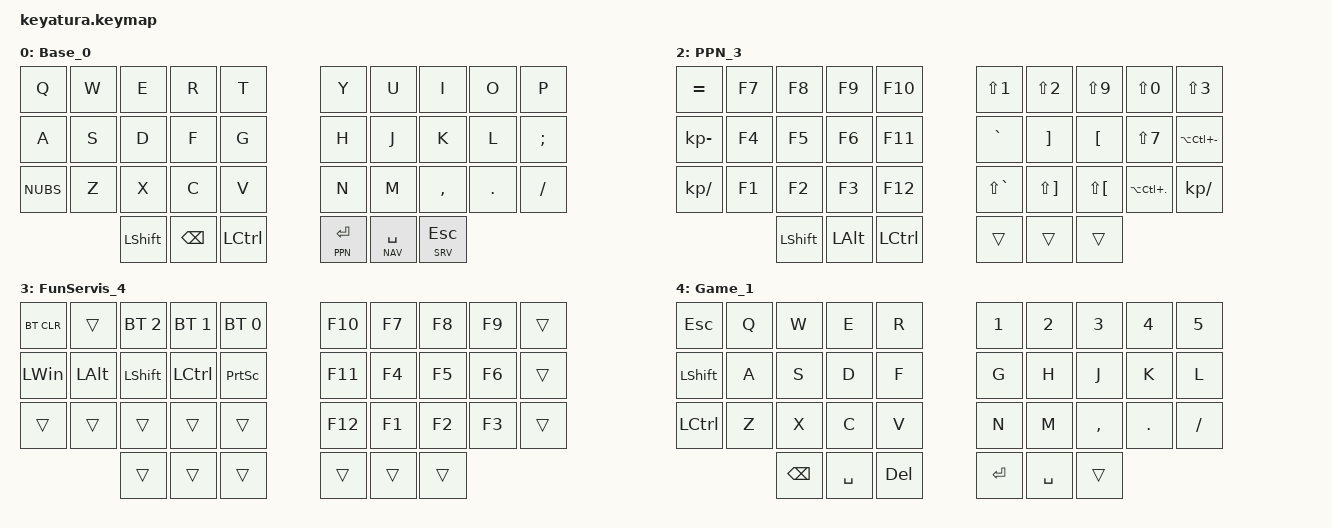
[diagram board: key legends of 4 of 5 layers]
#include <behaviors.dtsi> 
#include <dt-bindings/zmk/bt.h>
#include <dt-bindings/zmk/keys.h>
#include <dt-bindings/zmk/outputs.h>
#include <dt-bindings/zmk/pointing.h>

#include <behaviors/vfx_indicator.dtsi>

#define U_TAPPING_TERM 220
#define U_QUICK_TAP 200

#define BASE  0
#define NAV   1
#define PPN   2
#define SRV   3
#define GAME  4



/ {
    combos {
    compatible = "zmk,combos";
    timeout-ms = <20>;
    require-prior-idle-ms = <250>;

    bootloaderRight {
        bindings = <&bootloader>;
        key-positions = <9 18 27>;
        layers = <0>;
    };
    bootloaderLeft {
        bindings = <&bootloader>;
        key-positions = <0 11 22>;
        layers = <0>;
    };

    combo_normal {
        key-positions = <6 7 8>;
        bindings = <&to BASE>;
    };
    combo_normalleft {
        key-positions = <1 2 3>;
        bindings = <&to BASE>;
        layers = <0 1 2>;
    };
    game {
        bindings = <&tog GAME>;
        key-positions = <18 29>;
    };
    gameleft {
        bindings = <&tog GAME>;
        key-positions = <0 24>;
    };
    combo_SRV {
        key-positions = <27 28>;
        bindings = <&sl SRV>;
        layers = <0 1 2>;
    };
    GoNav {
        bindings = <&tog NAV>;
        key-positions = <5 16>;
    };
    GoPPN {
        bindings = <&tog PPN>;
        key-positions = <0 1 2>;
    };

    Delete {
        bindings = <&kp DELETE>;
        key-positions = <8 9>;
        layers = <0 1 2>;
    };
    Delete2 {
        bindings = <&kp DELETE>;
        key-positions = <7 8>;
        layers = <0 1 2>;
    };

    screenshot {
        bindings = <&kp LG(LS(S))>;
        key-positions = <3 4>;
        layers = <0 1 2>;
    };

    eng {
        bindings = <&kp F16>;
        key-positions = <13 14>;
        layers = <0 1 2>;
    };
    rus {
        bindings = <&kp F17>;
        key-positions = <15 16>;
        layers = <0 1 2>;
    };

    ParaLeft {
        bindings = <&kp LS(N9)>;
        key-positions = <23 24>;
        layers = <0 1 2>;
    };
    greatt {
        bindings = <&kp LC(LA(P))>;
        key-positions = <25 26>;
        layers = <0 1 2>;
    };
    circumflex {
        bindings = <&kp LS(N6)>;
        key-positions = <5 6>;
        layers = <0 1 2>;
    };

    fullscrenRight {
        bindings = <&kp F11>;
        key-positions = <6 15>;
        layers = <0 1 2>;
    };
    fullscreenLeft {
        bindings = <&kp F11>;
        key-positions = <3 14>;
        layers = <0 1 2>;
        };
    };

    behaviors {
        u_mt: u_mt {
            compatible = "zmk,behavior-hold-tap";
            #binding-cells = <2>;
            tapping-term-ms = <U_TAPPING_TERM>;
            quick-tap-ms = <U_QUICK_TAP>;
            flavor = "tap-preferred";
            bindings = <&kp>, <&kp>;
        };

        u_lt: u_lt {
            compatible = "zmk,behavior-hold-tap";
            #binding-cells = <2>;
            tapping-term-ms = <U_TAPPING_TERM>;
            quick-tap-ms = <U_QUICK_TAP>;
            flavor = "tap-preferred";
            bindings = <&mo>, <&kp>;
        };
    };

    keymap {
        compatible = "zmk,keymap";

        Base {
            display-name = "Base_0";
            bindings = <
            // ╭─────────────┬─────────────┬─────────────┬─────────────┬─────────────╮Bse╭─────────────┬─────────────┬─────────────┬─────────────┬─────────────╮
                    &kp Q         &kp W         &kp E         &kp R         &kp T             &kp Y         &kp U         &kp I         &kp O         &kp P
            // ├─────────────┼─────────────┼─────────────┼─────────────┼─────────────┤ 0 ├─────────────┼─────────────┼─────────────┼─────────────┼─────────────┤
                    &kp A         &kp S         &kp D         &kp F         &kp G             &kp H         &kp J         &kp K         &kp L        &kp SEMI
            // ├─────────────┼─────────────┼─────────────┼─────────────┼─────────────┤Bse├─────────────┼─────────────┼─────────────┼─────────────┼─────────────┤
                   &kp NUBS       &kp Z         &kp X         &kp C         &kp V             &kp N         &kp M       &kp COMMA      &kp DOT       &kp FSLH
            // ╰─────────────┴─────────────┼─────────────┼─────────────┼─────────────┤ 0 ├─────────────┼─────────────┼─────────────┼─────────────┴─────────────╯
                                              &kp LSHFT      &kp BSPC     &kp LCTRL        &lt PPN RET  &lt NAV SPACE  &lt SRV ESC  
            //                             ╰─────────────┴─────────────┴─────────────╯Bse╰─────────────┴─────────────┴─────────────╯
            >;
        };

        Navigation {
            display-name = "NavNam_2";
            bindings = <
            // ╭─────────────┬─────────────┬─────────────┬─────────────┬─────────────╮Nav╭─────────────┬─────────────┬─────────────┬─────────────┬─────────────╮
                  &kp EQUAL       &kp N7        &kp N8        &kp N9       &kp RBKT          &kp ESC      &kp PG_UP       &kp UP      &kp PG_DN      &kp F11
            // ├─────────────┼─────────────┼─────────────┼─────────────┼─────────────┤ 1 ├─────────────┼─────────────┼─────────────┼─────────────┼─────────────┤
                 &kp KP_MINUS     &kp N4        &kp N5        &kp N6     &kp KP_PLUS         &kp RET      &kp LEFT      &kp DOWN      &kp RIGHT      &kp LSHF
            // ├─────────────┼─────────────┼─────────────┼─────────────┼─────────────┤Nav├─────────────┼─────────────┼─────────────┼─────────────┼─────────────┤
                 &kp KP_SLASH     &kp N1        &kp N2        &kp N3   &kp KP_MULTIPLY       &kp TAB    &kp C_VOL_DN  &kp C_VOL_UP  &kp LA(LC(DOT)) T&kp LCTRL
            // ╰─────────────┴─────────────┼─────────────┼─────────────┼─────────────┤ 1 ├─────────────┼─────────────┼─────────────┼─────────────┴─────────────╯
                                              &kp SPACE     &kp BSPC       &kp N0            &kp RET      &kp SPACE       &trans
            //                             ╰─────────────┴─────────────┴─────────────╯Nav╰─────────────┴─────────────┴─────────────╯
            >;
        };

        PPN {
            display-name = "PPN_3";
            bindings = <
            // ╭─────────────┬─────────────┬─────────────┬─────────────┬─────────────╮PPN╭─────────────┬─────────────┬─────────────┬─────────────┬─────────────╮
                  &kp EQUAL       &kp F7        &kp F8        &kp F9       &kp F10          &kp LS(N1)    &kp LS(N2)    &kp LS(N9)    &kp LS(N0)    &kp LS(N3)
            // ├─────────────┼─────────────┼─────────────┼─────────────┼─────────────┤ 2 ├─────────────┼─────────────┼─────────────┼─────────────┼─────────────┤
                 &kp KP_MINUS     &kp F4        &kp F5        &kp F6       &kp F11          &kp GRAVE      &kp RBKT      &kp LBKT    &kp LS(N7) &kp LA(LC(MINUS))
            // ├─────────────┼─────────────┼─────────────┼─────────────┼─────────────┤PPN├─────────────┼─────────────┼─────────────┼─────────────┼─────────────┤
                 &kp KP_SLASH     &kp F1        &kp F2        &kp F3       &kp F12        &kp LS(GRAVE)  &kp LS(RBKT) &kp LS(LBKT) &kp LA(LC(DOT)) &kp KP_SLASH
            // ╰─────────────┴─────────────┼─────────────┼─────────────┼─────────────┤ 2 ├─────────────┼─────────────┼─────────────┼─────────────┴─────────────╯
                                              &kp LSHFT      &kp LALT     &kp LCTRL           &trans        &trans        &trans
            //                             ╰─────────────┴─────────────┴─────────────╯PPN╰─────────────┴─────────────┴─────────────╯
            >;
        };

        SRV {
            display-name = "FunServis_4";
            bindings = <
            // ╭─────────────┬─────────────┬─────────────┬─────────────┬─────────────╮SRV╭─────────────┬─────────────┬─────────────┬─────────────┬─────────────╮
                  &bt BT_CLR      &trans     &bt BT_SEL 2  &bt BT_SEL 1  &bt BT_SEL 0        &kp F10        &kp F7        &kp F8        &kp F9        &trans
            // ├─────────────┼─────────────┼─────────────┼─────────────┼─────────────┤ 3 ├─────────────┼─────────────┼─────────────┼─────────────┼─────────────┤
                   &kp LWIN     &kp LALT      &kp LSHFT     &kp LCTRL     &kp PSCRN          &kp F11        &kp F4        &kp F5        &kp F6        &trans
            // ├─────────────┼─────────────┼─────────────┼─────────────┼─────────────┤SRV├─────────────┼─────────────┼─────────────┼─────────────┼─────────────┤
                    &trans        &trans        &trans        &trans        &trans           &kp F12        &kp F1        &kp F2        &kp F3        &trans
            // ╰─────────────┴─────────────┼─────────────┼─────────────┼─────────────┤ 3 ├─────────────┼─────────────┼─────────────┼─────────────┴─────────────╯
                                                &trans        &trans        &trans            &trans        &trans        &trans
            //                             ╰─────────────┴─────────────┴─────────────╯SRV╰─────────────┴─────────────┴─────────────╯
            >;
        };
    
        Game {
            display-name = "Game_1";
            bindings = <
            // ╭─────────────┬─────────────┬─────────────┬─────────────┬─────────────╮Gam╭─────────────┬─────────────┬─────────────┬─────────────┬─────────────╮
                   &kp ESC        &kp Q         &kp W         &kp E         &kp R             &kp N1        &kp N2        &kp N3        &kp N4        &kp N5
            // ├─────────────┼─────────────┼─────────────┼─────────────┼─────────────┤ 4 ├─────────────┼─────────────┼─────────────┼─────────────┼─────────────┤
                  &kp LSHFT       &kp A         &kp S         &kp D         &kp F             &kp G         &kp H         &kp J         &kp K         &kp L
            // ├─────────────┼─────────────┼─────────────┼─────────────┼─────────────┤Gam├─────────────┼─────────────┼─────────────┼─────────────┼─────────────┤
                  &kp LCTRL       &kp Z         &kp X         &kp C         &kp V             &kp N         &kp M       &kp COMMA      &kp DOT       &kp FSLH
            // ╰─────────────┴─────────────┼─────────────┼─────────────┼─────────────┤ 4 ├─────────────┼─────────────┼─────────────┼─────────────┴─────────────╯
                                               &kp BSPC     &kp SPACE      &kp DEL           &kp RET      &kp SPACE       &trans
            //                             ╰─────────────┴─────────────┴─────────────╯Gam╰─────────────┴─────────────┴─────────────╯
            >;
        };
    };

    conditional_layers { compatible = "zmk,conditional-layers"; };
};
